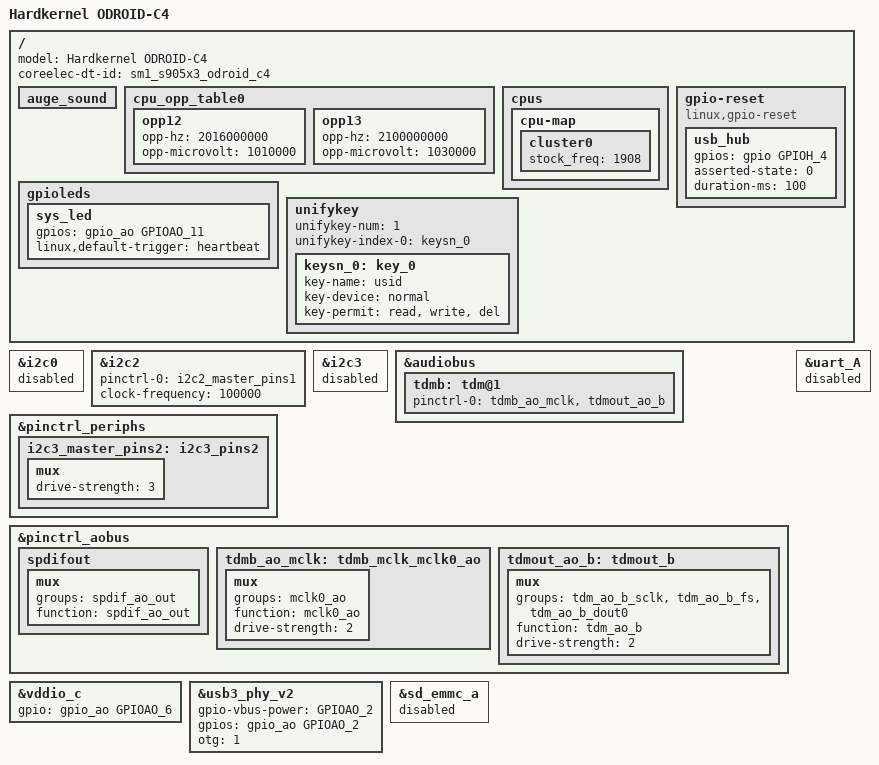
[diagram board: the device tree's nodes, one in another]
#include "sm1_s905x3_4g_1gbit.dts"

/{
	model = "Hardkernel ODROID-C4";
	coreelec-dt-id = "sm1_s905x3_odroid_c4";

	/delete-node/ memory@00000000;
	/delete-node/ rtc;
	/delete-node/ aml_bt;
	/delete-node/ aml_wifi;
	/delete-node/ wifi_pwm_conf;

	auge_sound {
		/delete-property/ avout_mute-gpios;
	};

	cpu_opp_table0: cpu_opp_table0 {
		opp12 {
			opp-hz = /bits/ 64 <2016000000>;
			opp-microvolt = <1010000>;
		};
		opp13 {
			opp-hz = /bits/ 64 <2100000000>;
			opp-microvolt = <1030000>;
		};
	};

	cpus:cpus {
		cpu-map {
			cluster0:cluster0 {
				stock_freq = <1908>;
			};
		};
	};

	gpioleds {
		sys_led {
			gpios = <&gpio_ao GPIOAO_11 GPIO_ACTIVE_HIGH>;
			linux,default-trigger = "heartbeat";
		};
	};

	gpio-reset {
		compatible = "linux,gpio-reset";
		usb_hub {
			gpios = <&gpio GPIOH_4 GPIO_ACTIVE_HIGH>;
			asserted-state = <0>;
			duration-ms = <100>;
		};
	};

	unifykey {
		unifykey-num = <1>;
		unifykey-index-0 = <&keysn_0>;

		keysn_0: key_0 {
			key-name = "usid";
			key-device = "normal";
			key-permit = "read","write","del";
		};
	};
};

&i2c0 {
	status = "disabled";
	/delete-property/ pinctrl-names;
	/delete-property/ pinctrl-0;
	/delete-node/ gt9xx@5d;
	/delete-node/ ftxx@38;
};

&i2c2 {
	status = "okay";
	pinctrl-0 = <&i2c2_master_pins1>;
	clock-frequency = <100000>;
};

&i2c3 {
	status = "disabled";
};

&audiobus {
	tdmb: tdm@1 {
		pinctrl-0 = <&tdmb_ao_mclk &tdmout_ao_b>;
	};
};

&pinctrl_periphs {
	/delete-node/ spdifout;

	i2c3_master_pins2: i2c3_pins2 {
		mux {
			drive-strength = <3>;
		};
	};
};

&pinctrl_aobus {
	spdifout: spdifout {
		mux { /* GPIOAO_10 */
			groups = "spdif_ao_out";
			function = "spdif_ao_out";
		};
	};

	tdmb_ao_mclk: tdmb_mclk_mclk0_ao {
		mux { /* GPIOAO_9 */
			groups = "mclk0_ao";
			function = "mclk0_ao";
			drive-strength = <2>;
		};
	};

	tdmout_ao_b: tdmout_b {
		mux { /* GPIOAO_8, GPIOAO_7, GPIOAO_4 */
			groups = "tdm_ao_b_sclk",
				"tdm_ao_b_fs",
				"tdm_ao_b_dout0";
			function = "tdm_ao_b";
			drive-strength = <2>;
		};
	};
};

&vddio_c {
	gpio = <&gpio_ao GPIOAO_6 GPIO_ACTIVE_HIGH>;
};

&usb3_phy_v2 {
	gpio-vbus-power = "GPIOAO_2";
	gpios = <&gpio_ao GPIOAO_2 GPIO_ACTIVE_HIGH>;
	otg = <1>;
};

&uart_A {
	status = "disabled";
};

&sd_emmc_a {
	 status = "disabled";
};
